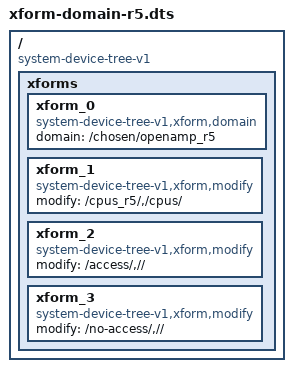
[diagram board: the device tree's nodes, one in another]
/dts-v1/;

/ {
        compatible = "system-device-tree-v1";
        xforms {
                // compatible = "system-device-tree-v1,xform";
                xform_0 {
                        compatible = "system-device-tree-v1,xform,domain";
                        domain = "/chosen/openamp_r5";
                };
                xform_1 {
                        compatible = "system-device-tree-v1,xform,modify";
                        modify = "/cpus_r5/,/cpus/";
                };
                xform_2 {
                        // modify to "nothing", is a remove operation
                        compatible = "system-device-tree-v1,xform,modify";
                        modify = "/access/,//";
                };
                xform_3 {
                        // modify to "nothing", is a remove operation
                        compatible = "system-device-tree-v1,xform,modify";
                        modify = "/no-access/,//";
                };
        };
};
